AUTOSAR XML (schema 4-0-3)
package /ComponentTypes
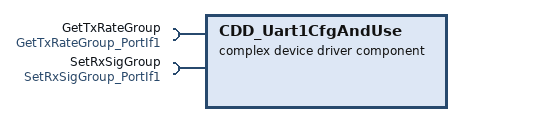
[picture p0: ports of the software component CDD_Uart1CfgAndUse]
  complex device driver sw component type CDD_Uart1CfgAndUse
    require port GetTxRateGroup: client-com-spec=Oper, required-interface=GetTxRateGroup_PortIf1
    require port SetRxSigGroup: client-com-spec=Oper, required-interface=SetRxSigGroup_PortIf1
    behavior CDD_Uart1CfgAndUse_InternalBehavior
      exclusive area ExclsvAr1Uart1DrvrTxRxBuf
      ar-typed-per-instance-memorys:
        13 x data, all with sw-calibration-access=READ-ONLY:
          PrevDmaTrfCnt: type=uint16
          Uart1100MilliSecBufCnt: type=Ary1D_u8_2048_Uart1CfgAndUse
          Uart1100MilliSecReadCmpl: type=uint8
          Uart110MilliSecBufCnt: type=Ary1D_u8_2048_Uart1CfgAndUse
          Uart110MilliSecReadCmpl: type=uint8
          Uart12MilliSecBufCnt: type=Ary1D_u8_2048_Uart1CfgAndUse
          Uart1DiagcFrmErrCntr: type=uint32
          Uart1DiagcOvrrunErrCntr: type=uint32
          Uart1DiagcParErrCntr: type=uint32
          Uart1DiagcRxMaxDataErrCntr: type=uint32
          Uart1NrOfPnd100MilliSecFrmCnt: type=uint8
          Uart1NrOfPnd10MilliSecFrmCnt: type=uint8
          Uart1RxPrevLoopDataUnread: type=uint8
      5 x timing event:
        CDD_Uart1CfgAndUse_InitEvent: start-on-event=Uart1CfgAndUseInit1, period=0
        TMT_Uart1CfgAndUsePer1: start-on-event=Uart1CfgAndUsePer1, period=0.002
        TMT_Uart1CfgAndUsePer2: start-on-event=Uart1CfgAndUsePer2, period=0.002
        TMT_Uart1CfgAndUsePer3: start-on-event=Uart1CfgAndUsePer3, period=0.01
        TMT_Uart1CfgAndUsePer4: start-on-event=Uart1CfgAndUsePer4, period=0.1
      5 x runnable:
        Uart1CfgAndUseInit1
        Uart1CfgAndUsePer1
          sync call SC_SetRxSigGroup_Oper: operation=SetRxSigGroup.Oper, timeout=0
        Uart1CfgAndUsePer2: can-enter-exclusive-area=ExclsvAr1Uart1DrvrTxRxBuf
          sync call SC_GetTxRateGroup_Oper: operation=GetTxRateGroup.Oper, timeout=0
        Uart1CfgAndUsePer3
          sync call SC_GetTxRateGroup_Oper: operation=GetTxRateGroup.Oper, timeout=0
        Uart1CfgAndUsePer4
          sync call SC_GetTxRateGroup_Oper: operation=GetTxRateGroup.Oper, timeout=0
  swc implementation CDD_Uart1CfgAndUse_Implementation: behavior=CDD_Uart1CfgAndUse_InternalBehavior
    code-descriptors:
      code Default: artifact-descriptors=autosar-engineering-object={short-label=Default, category=SWSRC}
